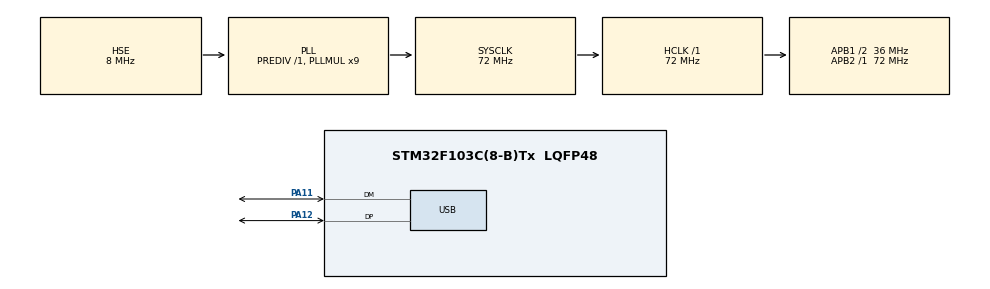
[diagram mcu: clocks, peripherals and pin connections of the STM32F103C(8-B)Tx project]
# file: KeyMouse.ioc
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Mcu.Family=STM32F1
Mcu.Name=STM32F103C(8-B)Tx
Mcu.Package=LQFP48
NVIC.PriorityGroup=NVIC_PRIORITYGROUP_4
NVIC.USB_LP_CAN1_RX0_IRQn=true\:0\:0\:false\:false\:true\:false\:true
PA11.Mode=Device
PA11.Signal=USB_DM
PA12.Mode=Device
PA12.Signal=USB_DP
PA13.Mode=JTAG_5_pins
PA13.Signal=SYS_JTMS-SWDIO
PA14.Mode=JTAG_5_pins
PA14.Signal=SYS_JTCK-SWCLK
PA15.Mode=JTAG_5_pins
PA15.Signal=SYS_JTDI
PB3.Mode=JTAG_5_pins
PB3.Signal=SYS_JTDO-TRACESWO
PB4.Mode=JTAG_5_pins
PB4.Signal=SYS_NJTRST
PC14-OSC32_IN.Mode=LSE-External-Oscillator
PC14-OSC32_IN.Signal=RCC_OSC32_IN
PC15-OSC32_OUT.Mode=LSE-External-Oscillator
PC15-OSC32_OUT.Signal=RCC_OSC32_OUT
PD0-OSC_IN.Mode=HSE-External-Oscillator
PD0-OSC_IN.Signal=RCC_OSC_IN
PD1-OSC_OUT.Mode=HSE-External-Oscillator
PD1-OSC_OUT.Signal=RCC_OSC_OUT
ProjectManager.HeapSize=0x200
ProjectManager.StackSize=0x400
ProjectManager.TargetToolchain=STM32CubeIDE
RCC.AHBFreq_Value=72000000
RCC.APB1CLKDivider=RCC_HCLK_DIV2
RCC.APB1Freq_Value=36000000
RCC.APB1TimFreq_Value=72000000
RCC.APB2Freq_Value=72000000
RCC.APB2TimFreq_Value=72000000
RCC.HCLKFreq_Value=72000000
RCC.PLLMUL=RCC_PLL_MUL9
RCC.SYSCLKFreq_VALUE=72000000
RCC.SYSCLKSource=RCC_SYSCLKSOURCE_PLLCLK
RCC.USBFreq_Value=48000000
RCC.USBPrescaler=RCC_USBCLKSOURCE_PLL_DIV1_5
USB.low_power_enable=DISABLE
USB.lpm_enable=DISABLE
USB_DEVICE.CLASS_NAME_FS=CUSTOM_HID
USB_DEVICE.LANGID_STRING=1033
USB_DEVICE.USBD_CUSTOMHID_OUTREPORT_BUF_SIZE=64
USB_DEVICE.USBD_CUSTOM_HID_REPORT_DESC_SIZE=2
USB_DEVICE.USBD_MAX_NUM_INTERFACES=1
USB_DEVICE.VID=1
USB_DEVICE.VirtualMode=CustomHid
USB_DEVICE.VirtualModeFS=Custom_Hid_FS
VP_USB_DEVICE_VS_USB_DEVICE_CUSTOM_HID_FS.Mode=CUSTOM_HID_FS
board=custom

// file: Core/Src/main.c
/* USER CODE BEGIN Header */
/**
  ******************************************************************************
  * @file           : main.c
  * @brief          : Main program body
  ******************************************************************************
  * @attention
  *
  * <h2><center>&copy; Copyright (c) 2019 STMicroelectronics.
  * All rights reserved.</center></h2>
  *
  * This software component is licensed by ST under BSD 3-Clause license,
  * the "License"; You may not use this file except in compliance with the
  * License. You may obtain a copy of the License at:
  *                        opensource.org/licenses/BSD-3-Clause
  *
  ******************************************************************************
  */
/* USER CODE END Header */

#include "main.h"
#include "usb_device.h"
#include "usbd_custom_hid_if.h"

/* USER CODE BEGIN PD */
  // HID Mouse
  struct mouseHID_t {
	  uint8_t reportid;
      uint8_t buttons;
      int8_t x;
      int8_t y;
      int8_t wheel;
  };
/* USER CODE END PD */

/* USER CODE BEGIN PV */
	uint8_t sendbuffer[12]={0x01,0x08,0x00,0x00,0x00,0x00,0x00,0x00,0x00,0x00,0x00,0x00,0x00};
	uint8_t sendbuffer2[12]={0x01,0x00,0x00,0x00,0x00,0x00,0x00,0x00,0x00,0x00,0x00,0x00,0x00};
/* USER CODE END PV */

void SystemClock_Config(void);
static void MX_GPIO_Init(void);

int main(void)
{
  /* USER CODE BEGIN 1 */
	  uint8_t HID_report[2]={3,1};
	 struct mouseHID_t mouseHID;
	 mouseHID.reportid=2;
	  mouseHID.buttons = 0;
	  mouseHID.x = 10;
	  mouseHID.y = 0;
	  mouseHID.wheel = 0;
  /* USER CODE END 1 */

  /* MCU Configuration--------------------------------------------------------*/

  /* Reset of all peripherals, Initializes the Flash interface and the Systick. */
  HAL_Init();

  /* Configure the system clock */
  SystemClock_Config();

  /* Initialize all configured peripherals */
  MX_GPIO_Init();
  MX_USB_DEVICE_Init();

  /* Infinite loop */
  while (1)
  {

		/* USER CODE BEGIN 3 */
		//HAL_GPIO_WritePin(LED_GPIO_Port, LED_Pin, GPIO_PIN_RESET);
		//HAL_GPIO_WritePin(LED_GPIO_Port, LED_Pin, GPIO_PIN_SET);
		if(hUsbDeviceFS.dev_state!=USBD_STATE_CONFIGURED)
		{
			HAL_Delay(1000);
			continue;
		}
		//媒体控制器
		HID_report[1]=0x01;//音量 + 按钮
		USBD_CUSTOM_HID_SendReport(&hUsbDeviceFS,HID_report,2);
		HAL_Delay(40);
		HID_report[1]=0x00;
		USBD_CUSTOM_HID_SendReport(&hUsbDeviceFS,HID_report,2);
		HAL_Delay(40);

		//键盘消息
		//USBD_CUSTOM_HID_SendReport(&hUsbDeviceFS,sendbuffer,9);//WIN按下
		//HAL_Delay(50);
		//USBD_CUSTOM_HID_SendReport(&hUsbDeviceFS,sendbuffer2,9);//WIN抬起
		//HAL_Delay(50);

		//鼠标消息
		USBD_CUSTOM_HID_SendReport(&hUsbDeviceFS,(uint8_t *)&mouseHID,sizeof(mouseHID));
		//HAL_Delay(50);

		HAL_Delay(1000);
  }
  /* USER CODE END 3 */
}

void SystemClock_Config(void)
{
  RCC_OscInitTypeDef RCC_OscInitStruct = {0};
  RCC_ClkInitTypeDef RCC_ClkInitStruct = {0};
  RCC_PeriphCLKInitTypeDef PeriphClkInit = {0};

  /** Initializes the CPU, AHB and APB busses clocks
  */
  RCC_OscInitStruct.OscillatorType = RCC_OSCILLATORTYPE_HSE;
  RCC_OscInitStruct.HSEState = RCC_HSE_ON;
  RCC_OscInitStruct.HSEPredivValue = RCC_HSE_PREDIV_DIV1;
  RCC_OscInitStruct.HSIState = RCC_HSI_ON;
  RCC_OscInitStruct.PLL.PLLState = RCC_PLL_ON;
  RCC_OscInitStruct.PLL.PLLSource = RCC_PLLSOURCE_HSE;
  RCC_OscInitStruct.PLL.PLLMUL = RCC_PLL_MUL9;
  if (HAL_RCC_OscConfig(&RCC_OscInitStruct) != HAL_OK)
  {
    Error_Handler();
  }
  /** Initializes the CPU, AHB and APB busses clocks
  */
  RCC_ClkInitStruct.ClockType = RCC_CLOCKTYPE_HCLK|RCC_CLOCKTYPE_SYSCLK
                              |RCC_CLOCKTYPE_PCLK1|RCC_CLOCKTYPE_PCLK2;
  RCC_ClkInitStruct.SYSCLKSource = RCC_SYSCLKSOURCE_PLLCLK;
  RCC_ClkInitStruct.AHBCLKDivider = RCC_SYSCLK_DIV1;
  RCC_ClkInitStruct.APB1CLKDivider = RCC_HCLK_DIV2;
  RCC_ClkInitStruct.APB2CLKDivider = RCC_HCLK_DIV1;

  if (HAL_RCC_ClockConfig(&RCC_ClkInitStruct, FLASH_LATENCY_2) != HAL_OK)
  {
    Error_Handler();
  }
  PeriphClkInit.PeriphClockSelection = RCC_PERIPHCLK_USB;
  PeriphClkInit.UsbClockSelection = RCC_USBCLKSOURCE_PLL_DIV1_5;
  if (HAL_RCCEx_PeriphCLKConfig(&PeriphClkInit) != HAL_OK)
  {
    Error_Handler();
  }
}

static void MX_GPIO_Init(void)
{

  /* GPIO Ports Clock Enable */
  __HAL_RCC_GPIOC_CLK_ENABLE();
  __HAL_RCC_GPIOD_CLK_ENABLE();
  __HAL_RCC_GPIOA_CLK_ENABLE();
  __HAL_RCC_GPIOB_CLK_ENABLE();

}

void Error_Handler(void)
{
}

/************************ (C) COPYRIGHT STMicroelectronics *****END OF FILE****/
